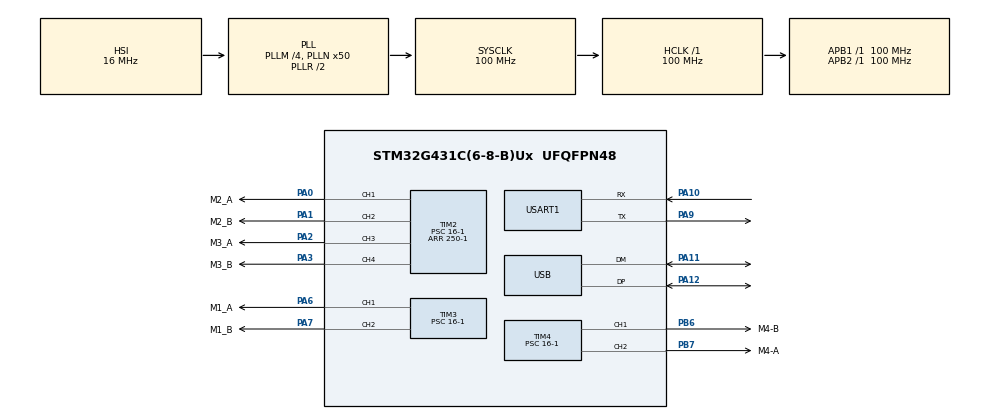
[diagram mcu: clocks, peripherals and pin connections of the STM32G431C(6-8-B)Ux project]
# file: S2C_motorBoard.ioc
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Mcu.Family=STM32G4
Mcu.Name=STM32G431C(6-8-B)Ux
Mcu.Package=UFQFPN48
NVIC.PriorityGroup=NVIC_PRIORITYGROUP_4
NVIC.TIM7_IRQn=true\:1\:0\:true\:false\:true\:true\:true\:true
NVIC.USB_HP_IRQn=true\:0\:0\:false\:false\:true\:true\:true\:true
NVIC.USB_LP_IRQn=true\:0\:0\:false\:false\:true\:false\:true\:true
PA0.GPIO_Label=M2_A
PA0.Signal=S_TIM2_CH1
PA1.GPIO_Label=M2_B
PA1.Signal=S_TIM2_CH2
PA10.Mode=Asynchronous
PA10.Signal=USART1_RX
PA11.Mode=Device
PA11.Signal=USB_DM
PA12.Mode=Device
PA12.Signal=USB_DP
PA13.Mode=Trace_Asynchronous_SW
PA13.Signal=SYS_JTMS-SWDIO
PA14.Mode=Trace_Asynchronous_SW
PA14.Signal=SYS_JTCK-SWCLK
PA2.GPIO_Label=M3_A
PA2.Signal=S_TIM2_CH3
PA3.GPIO_Label=M3_B
PA3.Signal=S_TIM2_CH4
PA6.GPIO_Label=M1_A
PA6.Signal=S_TIM3_CH1
PA7.GPIO_Label=M1_B
PA7.Signal=S_TIM3_CH2
PA9.Mode=Asynchronous
PA9.Signal=USART1_TX
PB3.Mode=Trace_Asynchronous_SW
PB3.Signal=SYS_JTDO-SWO
PB6.GPIO_Label=M4-B
PB6.Signal=S_TIM4_CH1
PB7.GPIO_Label=M4-A
PB7.Signal=S_TIM4_CH2
ProjectManager.HeapSize=0x200
ProjectManager.StackSize=0x400
ProjectManager.TargetToolchain=STM32CubeIDE
RCC.ADC12Freq_Value=100000000
RCC.AHBFreq_Value=100000000
RCC.APB1Freq_Value=100000000
RCC.APB1TimFreq_Value=100000000
RCC.APB2Freq_Value=100000000
RCC.APB2TimFreq_Value=100000000
RCC.CK48CLockSelection=RCC_USBCLKSOURCE_HSI48
RCC.CortexFreq_Value=100000000
RCC.EXTERNAL_CLOCK_VALUE=12288000
RCC.HCLKFreq_Value=100000000
RCC.HSE_VALUE=8000000
RCC.HSI48_VALUE=48000000
RCC.HSI_VALUE=16000000
RCC.LSE_VALUE=32768
RCC.PLLM=RCC_PLLM_DIV4
RCC.PLLN=50
RCC.SYSCLKFreq_VALUE=100000000
RCC.SYSCLKSource=RCC_SYSCLKSOURCE_PLLCLK
RCC.USBFreq_Value=48000000
RCC.VCOOutputFreq_Value=200000000
SH.S_TIM2_CH1.0=TIM2_CH1,PWM Generation1 CH1
SH.S_TIM2_CH2.0=TIM2_CH2,PWM Generation2 CH2
SH.S_TIM2_CH3.0=TIM2_CH3,PWM Generation3 CH3
SH.S_TIM2_CH4.0=TIM2_CH4,PWM Generation4 CH4
SH.S_TIM3_CH1.0=TIM3_CH1,PWM Generation1 CH1
SH.S_TIM3_CH2.0=TIM3_CH2,PWM Generation2 CH2
SH.S_TIM4_CH1.0=TIM4_CH1,PWM Generation1 CH1
SH.S_TIM4_CH2.0=TIM4_CH2,PWM Generation2 CH2
TIM1.PeriodNoDither=250-1
TIM1.Prescaler=16-1
TIM1.TIM_MasterOutputTrigger=TIM_TRGO_UPDATE
TIM1.TIM_MasterSlaveMode=TIM_MASTERSLAVEMODE_ENABLE
TIM2.Channel-PWM\ Generation1\ CH1=TIM_CHANNEL_1
TIM2.Channel-PWM\ Generation2\ CH2=TIM_CHANNEL_2
TIM2.Channel-PWM\ Generation3\ CH3=TIM_CHANNEL_3
TIM2.Channel-PWM\ Generation4\ CH4=TIM_CHANNEL_4
TIM2.OCPolarity_2=TIM_OCPOLARITY_HIGH
TIM2.OCPolarity_4=TIM_OCPOLARITY_HIGH
TIM2.PeriodNoDither=250-1
TIM2.Prescaler=16-1
TIM2.PulseNoDither_1=0
TIM2.PulseNoDither_2=0
TIM2.PulseNoDither_3=0
TIM2.PulseNoDither_4=0
TIM3.Channel-PWM\ Generation1\ CH1=TIM_CHANNEL_1
TIM3.Channel-PWM\ Generation2\ CH2=TIM_CHANNEL_2
TIM3.OCPolarity_2=TIM_OCPOLARITY_HIGH
TIM3.PeriodNoDither=250-1
TIM3.Prescaler=16-1
TIM3.PulseNoDither_1=0
TIM3.PulseNoDither_2=0
TIM3.TIM_MasterOutputTrigger=TIM_TRGO_UPDATE
TIM4.Channel-PWM\ Generation1\ CH1=TIM_CHANNEL_1
TIM4.Channel-PWM\ Generation2\ CH2=TIM_CHANNEL_2
TIM4.OCPolarity_1=TIM_OCPOLARITY_HIGH
TIM4.PeriodNoDither=250-1
TIM4.Prescaler=16-1
TIM4.PulseNoDither_1=0
TIM4.PulseNoDither_2=0
TIM4.TIM_MasterOutputTrigger=TIM_TRGO_UPDATE
TIM7.PeriodNoDither=99
TIM7.Prescaler=10000-1
USART1.VirtualMode-Asynchronous=VM_ASYNC
USB_DEVICE.CLASS_NAME_FS=CDC
USB_DEVICE.VirtualMode=Cdc
USB_DEVICE.VirtualModeFS=Cdc_FS
VP_SYS_VS_DBSignals.Mode=DisableDeadBatterySignals
VP_TIM1_VS_ClockSourceINT.Mode=Internal
VP_TIM2_VS_ClockSourceINT.Mode=Internal
VP_TIM2_VS_ClockSourceITR.Mode=TriggerSource_ITR0
VP_TIM2_VS_ControllerModeTrigger.Mode=Trigger Mode
VP_TIM3_VS_ClockSourceINT.Mode=Internal
VP_TIM3_VS_ClockSourceITR.Mode=TriggerSource_ITR0
VP_TIM3_VS_ControllerModeTrigger.Mode=Trigger Mode
VP_TIM4_VS_ClockSourceINT.Mode=Internal
VP_TIM4_VS_ClockSourceITR.Mode=TriggerSource_ITR0
VP_TIM4_VS_ControllerModeTrigger.Mode=Trigger Mode
VP_TIM7_VS_ClockSourceINT.Mode=Enable_Timer
VP_USB_DEVICE_VS_USB_DEVICE_CDC_FS.Mode=CDC_FS
board=custom

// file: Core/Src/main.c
/* USER CODE BEGIN Header */
/**
 ******************************************************************************
 * @file           : main.c
 * @brief          : Main program body
 ******************************************************************************
 * @attention
 *
 * Copyright (c) 2025 STMicroelectronics.
 * All rights reserved.
 *
 * This software is licensed under terms that can be found in the LICENSE file
 * in the root directory of this software component.
 * If no LICENSE file comes with this software, it is provided AS-IS.
 *
 ******************************************************************************
 */
/* USER CODE END Header */
#include "main.h"
#include "tim.h"
#include "usart.h"
#include "usb_device.h"
#include "gpio.h"

/* USER CODE BEGIN Includes */
#include "usbd_cdc_if.h"
#include "motor.h"
#include "usb_handler.h"

/* USER CODE END Includes */

void SystemClock_Config(void);

int main(void)
{

  /* MCU Configuration--------------------------------------------------------*/

  /* Reset of all peripherals, Initializes the Flash interface and the Systick. */
  HAL_Init();

  /* Configure the system clock */
  SystemClock_Config();

  /* Initialize all configured peripherals */
  MX_GPIO_Init();
  MX_USART1_UART_Init();
  MX_USB_Device_Init();
  MX_TIM2_Init();
  MX_TIM3_Init();
  MX_TIM4_Init();
  MX_TIM1_Init();
  MX_TIM7_Init();
  /* USER CODE BEGIN 2 */
  HAL_TIM_PWM_Start(&htim2, TIM_CHANNEL_1);
  HAL_TIM_PWM_Start(&htim2, TIM_CHANNEL_2);
  HAL_TIM_PWM_Start(&htim2, TIM_CHANNEL_3);
  HAL_TIM_PWM_Start(&htim2, TIM_CHANNEL_4);
  HAL_TIM_PWM_Start(&htim3, TIM_CHANNEL_1);
  HAL_TIM_PWM_Start(&htim3, TIM_CHANNEL_2);
  HAL_TIM_PWM_Start(&htim4, TIM_CHANNEL_1);
  HAL_TIM_PWM_Start(&htim4, TIM_CHANNEL_2);
  HAL_TIM_Base_Start(&htim1);
  HAL_TIM_Base_Start_IT(&htim7);

  //motor_test(20000,100);

  /* USER CODE END 2 */

  /* Infinite loop */
  /* USER CODE BEGIN WHILE */
	while (1)
	{
		//USB_SendTestFrame();
    /* USER CODE END WHILE */

	}
}

void SystemClock_Config(void)
{
  RCC_OscInitTypeDef RCC_OscInitStruct = {0};
  RCC_ClkInitTypeDef RCC_ClkInitStruct = {0};

  /** Configure the main internal regulator output voltage
  */
  HAL_PWREx_ControlVoltageScaling(PWR_REGULATOR_VOLTAGE_SCALE1);

  /** Initializes the RCC Oscillators according to the specified parameters
  * in the RCC_OscInitTypeDef structure.
  */
  RCC_OscInitStruct.OscillatorType = RCC_OSCILLATORTYPE_HSI|RCC_OSCILLATORTYPE_HSI48;
  RCC_OscInitStruct.HSIState = RCC_HSI_ON;
  RCC_OscInitStruct.HSICalibrationValue = RCC_HSICALIBRATION_DEFAULT;
  RCC_OscInitStruct.HSI48State = RCC_HSI48_ON;
  RCC_OscInitStruct.PLL.PLLState = RCC_PLL_ON;
  RCC_OscInitStruct.PLL.PLLSource = RCC_PLLSOURCE_HSI;
  RCC_OscInitStruct.PLL.PLLM = RCC_PLLM_DIV4;
  RCC_OscInitStruct.PLL.PLLN = 50;
  RCC_OscInitStruct.PLL.PLLP = RCC_PLLP_DIV2;
  RCC_OscInitStruct.PLL.PLLQ = RCC_PLLQ_DIV2;
  RCC_OscInitStruct.PLL.PLLR = RCC_PLLR_DIV2;
  if (HAL_RCC_OscConfig(&RCC_OscInitStruct) != HAL_OK)
  {
    Error_Handler();
  }

  /** Initializes the CPU, AHB and APB buses clocks
  */
  RCC_ClkInitStruct.ClockType = RCC_CLOCKTYPE_HCLK|RCC_CLOCKTYPE_SYSCLK
                              |RCC_CLOCKTYPE_PCLK1|RCC_CLOCKTYPE_PCLK2;
  RCC_ClkInitStruct.SYSCLKSource = RCC_SYSCLKSOURCE_PLLCLK;
  RCC_ClkInitStruct.AHBCLKDivider = RCC_SYSCLK_DIV1;
  RCC_ClkInitStruct.APB1CLKDivider = RCC_HCLK_DIV1;
  RCC_ClkInitStruct.APB2CLKDivider = RCC_HCLK_DIV1;

  if (HAL_RCC_ClockConfig(&RCC_ClkInitStruct, FLASH_LATENCY_3) != HAL_OK)
  {
    Error_Handler();
  }
}

void Error_Handler(void)
{
	__disable_irq();
	while (1)
	{
	}
}
